AUTOSAR XML (schema 4-2-1)
package /ComponentTypes
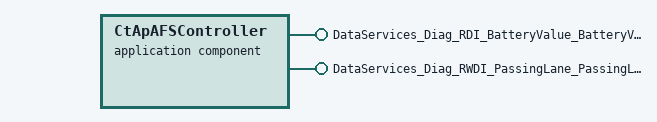
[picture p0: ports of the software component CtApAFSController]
  application sw component type CtApAFSController
    provide port DataServices_Diag_RDI_BatteryValue_BatteryValue: provided-com-specs=[{operation=ConditionCheckRead, queue-length=1}, {operation=ReadData, queue-length=1}], provided-interface=DataServices_Diag_RDI_BatteryValue_BatteryValue
    provide port DataServices_Diag_RWDI_PassingLane_PassingLane_PassingLane: provided-interface=DataServices_Diag_RWDI_PassingLane_PassingLane_PassingLane
      provided-com-specs:
        operation=ConditionCheckRead, queue-length=1
        operation=ReadData, queue-length=1
        operation=WriteData, queue-length=1
    behavior CtApAFSController_InternalBehavior
      5 x operation invoked event:
        OIT_DataServices_Diag_RDI_BatteryValue_BatteryValue_ConditionCheckRead_DataServices_Diag_RDI_BatteryValue_BatteryValue_C3B28864A: start-on-event=DataServices_Diag_RDI_BatteryValue_BatteryValue_ConditionCheckRead, operation=DataServices_Diag_RDI_BatteryValue_BatteryValue.ConditionCheckRead
        OIT_DataServices_Diag_RDI_BatteryValue_BatteryValue_ReadData_DataServices_Diag_RDI_BatteryValue_BatteryValue_ReadData: start-on-event=DataServices_Diag_RDI_BatteryValue_BatteryValue_ReadData, operation=DataServices_Diag_RDI_BatteryValue_BatteryValue.ReadData
        OIT_DataServices_Diag_RWDI_PassingLane_PassingLane_PassingLane_ConditionCheckRead_DataServices_Diag_RWDI_PassingLane_Pas5F15AC2B: start-on-event=DataServices_Diag_RWDI_PassingLane_PassingLane_PassingLane_ConditionCheckRead, operation=DataServices_Diag_RWDI_PassingLane_PassingLane_PassingLane.ConditionCheckRead
        OIT_DataServices_Diag_RWDI_PassingLane_PassingLane_PassingLane_ReadData_DataServices_Diag_RWDI_PassingLane_PassingLane_P8D71540F: start-on-event=DataServices_Diag_RWDI_PassingLane_PassingLane_PassingLane_ReadData, operation=DataServices_Diag_RWDI_PassingLane_PassingLane_PassingLane.ReadData
        OIT_DataServices_Diag_RWDI_PassingLane_PassingLane_PassingLane_WriteData_DataServices_Diag_RWDI_PassingLane_PassingLane_DA0BE9C4: start-on-event=DataServices_Diag_RWDI_PassingLane_PassingLane_PassingLane_WriteData, operation=DataServices_Diag_RWDI_PassingLane_PassingLane_PassingLane.WriteData
      init event CtApAFSController_InitEvent: start-on-event=RCtApAFSController_Init
      7 x runnable:
        DataServices_Diag_RDI_BatteryValue_BatteryValue_ConditionCheckRead
        DataServices_Diag_RDI_BatteryValue_BatteryValue_ReadData
        DataServices_Diag_RWDI_PassingLane_PassingLane_PassingLane_ConditionCheckRead
        DataServices_Diag_RWDI_PassingLane_PassingLane_PassingLane_ReadData
        DataServices_Diag_RWDI_PassingLane_PassingLane_PassingLane_WriteData
        RCtApAFSController_Init
        RCtApAFSControllerLogic
  swc implementation CtApAFSController_Implementation: behavior=CtApAFSController_InternalBehavior
    code-descriptors:
      code Default: artifact-descriptors=autosar-engineering-object={short-label=Default, category=SWSRC}
